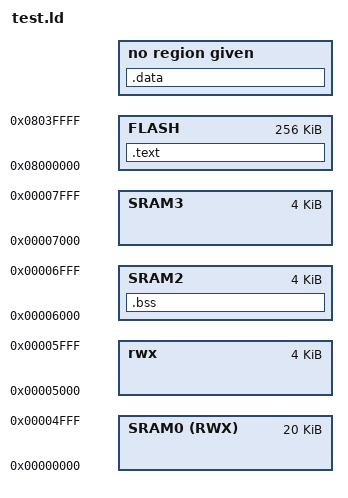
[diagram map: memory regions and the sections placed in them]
MEMORY {
	SRAM0(RWX) : ORIGIN = 0, LENGTH = 20K
	SRAM1(rwx : ORIGIN = 0x5000, LENGTH = 4K
	SRAM2 : ORIGIN = 0x6000, LENGTH = 4K
	SRAM3 : ORIGIN = 0x7000, LENGTH = 4K
	FLASH:  ORIGIN = 0x8000000,LENGTH = 256K
}

REGION_ALIAS("REGION_TEXT",FLASH);
REGION_ALIAS("REGION_RODATA",FLASH);
REGION_ALIAS("REGION_DATA",SRAM1);
REGION_ALIAS("REGION_BSS",SRAM2);
REGION_ALIAS("REGION_STK",SRAM3);

SECTIONS {
	.text: {
		. = ALIGN(0x80);/* 128 bytes align */
		. = ALIGN(0x4);	/* 4 bytes align */
		*(.text)
	} > REGION_TEXT

	.data: {
		data_start = .;
		*(.data)
	} > REGION_DATA

	.bss: {
		*(.bss)
	} > REGION_BSS
}
